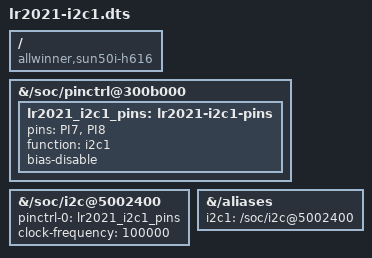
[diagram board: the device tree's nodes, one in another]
/*
 * LR2021: I2C1 on the 40-pin header for the I2C/Qwiic sockets of the carrier board.
 *   SDA = PI8 (pin 3), SCL = PI7 (pin 5), mux function "i2c1" (value 5 in pinctrl-sun50i-h616.c)
 *   -> /dev/i2c-1 (fixed by the alias below; without it the bus number depends on probe order)
 * Own pin group like lr2021-uart34 (does not rely on the kernel's i2c1-pi-pins group).
 * The carrier board has 4.7 kOhm pull-ups to 3.3 V, so the internal pull-ups stay off.
 * 100 kHz; for 400 kHz set clock-frequency = <400000> (all devices on the bus must support it).
 */
/dts-v1/;
/plugin/;
/ {
	compatible = "allwinner,sun50i-h616";

	fragment@0 {
		target-path = "/soc/pinctrl@300b000";
		__overlay__ {
			lr2021_i2c1_pins: lr2021-i2c1-pins {
				pins = "PI7", "PI8";
				function = "i2c1";
				bias-disable;
			};
		};
	};

	fragment@1 {
		target-path = "/soc/i2c@5002400";	/* i2c1 */
		__overlay__ {
			pinctrl-names = "default";
			pinctrl-0 = <&lr2021_i2c1_pins>;
			clock-frequency = <100000>;
			status = "okay";
		};
	};

	fragment@2 {
		target-path = "/aliases";
		__overlay__ {
			i2c1 = "/soc/i2c@5002400";
		};
	};
};
